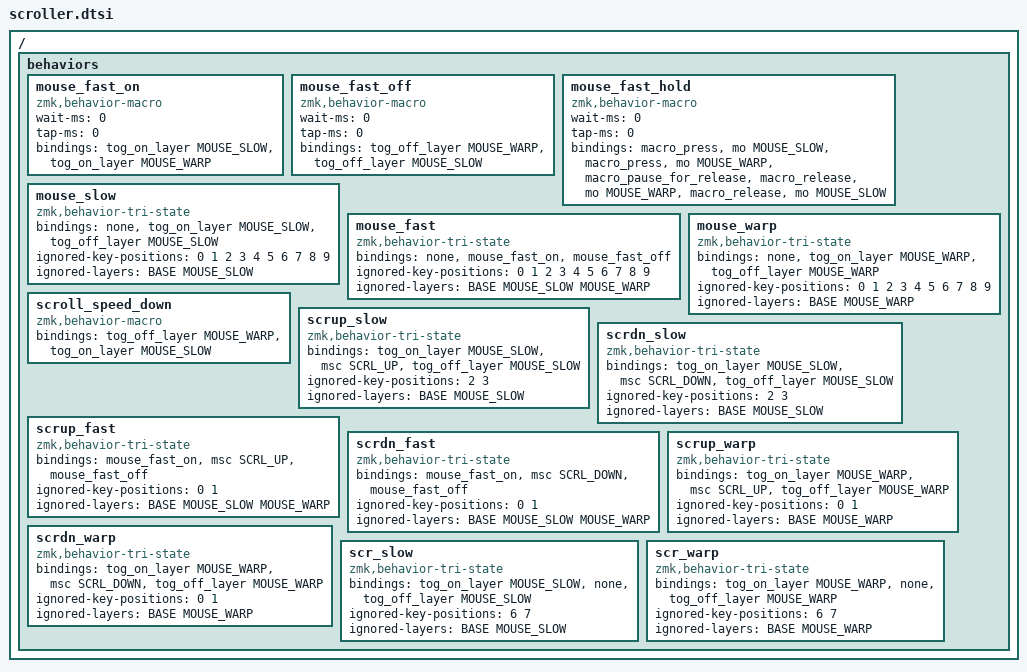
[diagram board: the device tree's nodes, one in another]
/ {
	behaviors {

		mouse_fast_on: mouse_fast_on {
			compatible = "zmk,behavior-macro";
			#binding-cells = <0>;
			wait-ms = <0>;
			tap-ms = <0>;
			bindings = <&tog_on_layer MOUSE_SLOW>, <&tog_on_layer MOUSE_WARP>;
		};

		mouse_fast_off: mouse_fast_off {
			compatible = "zmk,behavior-macro";
			#binding-cells = <0>;
			wait-ms = <0>;
			tap-ms = <0>;
			bindings = <&tog_off_layer MOUSE_WARP>, <&tog_off_layer MOUSE_SLOW>;
		};

		mouse_fast_hold: mouse_fast_hold {
			compatible = "zmk,behavior-macro";
			#binding-cells = <0>;
			wait-ms = <0>;
			tap-ms = <0>;
			bindings
				= <&macro_press &mo MOUSE_SLOW>
				, <&macro_press &mo MOUSE_WARP>
				, <&macro_pause_for_release>
				, <&macro_release &mo MOUSE_WARP>
				, <&macro_release &mo MOUSE_SLOW>;
		};

		mouse_slow: mouse_slow {
				compatible = "zmk,behavior-tri-state";
				#binding-cells = <0>;
				bindings = <&none>, <&tog_on_layer MOUSE_SLOW>, <&tog_off_layer MOUSE_SLOW>;
				ignored-key-positions = <0 1 2 3 4 5 6 7 8 9>;
				ignored-layers = <BASE MOUSE_SLOW>;
		};

		mouse_fast: mouse_fast {
				compatible = "zmk,behavior-tri-state";
				#binding-cells = <0>;
				bindings = <&none>, <&mouse_fast_on>, <&mouse_fast_off>;
				ignored-key-positions = <0 1 2 3 4 5 6 7 8 9>;
				ignored-layers = <BASE MOUSE_SLOW MOUSE_WARP>;
		};

		mouse_warp: mouse_warp {
				compatible = "zmk,behavior-tri-state";
				#binding-cells = <0>;
				bindings = <&none>, <&tog_on_layer MOUSE_WARP>, <&tog_off_layer MOUSE_WARP>;
				ignored-key-positions = <0 1 2 3 4 5 6 7 8 9>;
				ignored-layers = <BASE MOUSE_WARP>;
		};

		scroll_speed_down: scroll_speed_down {
			compatible = "zmk,behavior-macro";
			#binding-cells = <0>;
			bindings = <&tog_off_layer MOUSE_WARP>, <&tog_on_layer MOUSE_SLOW>;
		};


		scrup_slow: scrup_slow {
				compatible = "zmk,behavior-tri-state";
				#binding-cells = <0>;
				bindings = <&tog_on_layer MOUSE_SLOW>, <&msc SCRL_UP>, <&tog_off_layer MOUSE_SLOW>;
				ignored-key-positions = <2 3>;
				ignored-layers = <BASE MOUSE_SLOW>;
		};

		scrdn_slow: scrdn_slow {
				compatible = "zmk,behavior-tri-state";
				#binding-cells = <0>;
				bindings = <&tog_on_layer MOUSE_SLOW>, <&msc SCRL_DOWN>, <&tog_off_layer MOUSE_SLOW>;
				ignored-key-positions = <2 3>;
				ignored-layers = <BASE MOUSE_SLOW>;
		};

		scrup_fast: scrup_fast {
				compatible = "zmk,behavior-tri-state";
				#binding-cells = <0>;
				bindings = <&mouse_fast_on>, <&msc SCRL_UP>, <&mouse_fast_off>;
				ignored-key-positions = <0 1>;
				ignored-layers = <BASE MOUSE_SLOW MOUSE_WARP>;
		};

		scrdn_fast: scrdn_fast {
				compatible = "zmk,behavior-tri-state";
				#binding-cells = <0>;
				bindings = <&mouse_fast_on>, <&msc SCRL_DOWN>, <&mouse_fast_off>;
				ignored-key-positions = <0 1>;
				ignored-layers = <BASE MOUSE_SLOW MOUSE_WARP>;
		};

		scrup_warp: scrup_warp {
				compatible = "zmk,behavior-tri-state";
				#binding-cells = <0>;
				bindings = <&tog_on_layer MOUSE_WARP>, <&msc SCRL_UP>, <&tog_off_layer MOUSE_WARP>;
				ignored-key-positions = <0 1>;
				ignored-layers = <BASE MOUSE_WARP>;
		};

		scrdn_warp: scrdn_warp {
				compatible = "zmk,behavior-tri-state";
				#binding-cells = <0>;
				bindings = <&tog_on_layer MOUSE_WARP>, <&msc SCRL_DOWN>, <&tog_off_layer MOUSE_WARP>;
				ignored-key-positions = <0 1>;
				ignored-layers = <BASE MOUSE_WARP>;
		};


		scr_slow: scr_slow {
				compatible = "zmk,behavior-tri-state";
				#binding-cells = <0>;
				bindings = <&tog_on_layer MOUSE_SLOW>, <&none>, <&tog_off_layer MOUSE_SLOW>;
				ignored-key-positions = <6 7>;
				ignored-layers = <BASE MOUSE_SLOW>;
		};

		scr_warp: scr_warp {
				compatible = "zmk,behavior-tri-state";
				#binding-cells = <0>;
				bindings = <&tog_on_layer MOUSE_WARP>, <&none>, <&tog_off_layer MOUSE_WARP>;
				ignored-key-positions = <6 7>;
				ignored-layers = <BASE MOUSE_WARP>;
		};


	};
};
